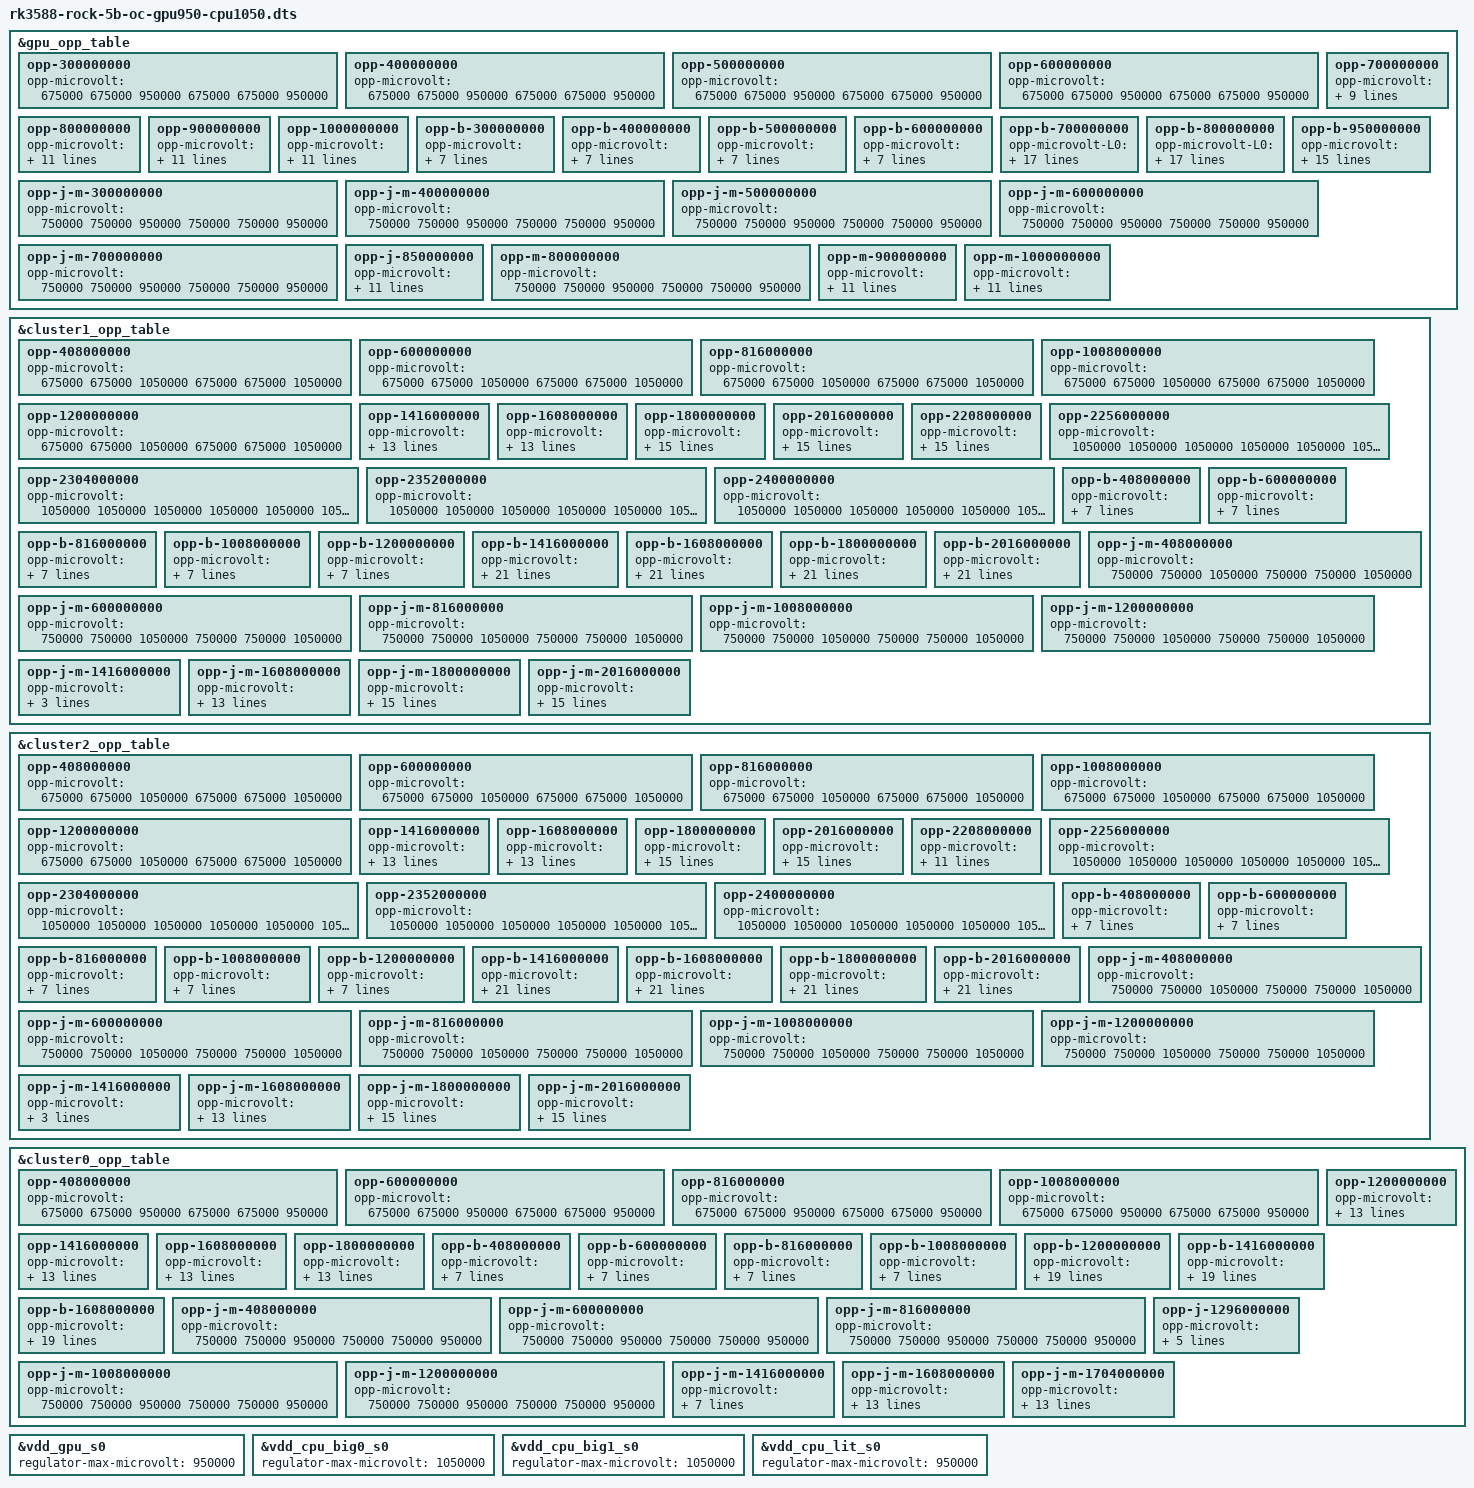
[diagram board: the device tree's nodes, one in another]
/dts-v1/;
/plugin/;

// RK3588 (ROCK 5B, vendor kernel) overclock: GPU 1 GHz OPP 950 mV, A76 top OPPs 1050 mV, A55 1.8 GHz OPP 925 mV.
// PVTPLL sets the real clocks from the voltage. Tested stable on one ROCK 5B (GPU PVTM level 5, A76 levels 6/7,
// A55 level 6) with glmark2 / all-core self-checking stress. Other chips (bins) may differ: if it does not boot,
// remove the FDTOVERLAYS line from extlinux/extlinux.conf on the boot partition from a PC.
// Generated by gen_oc.py from the kernel's rk3588-rock-5b.dtb; every OPP's max is raised so that the core and
// memory supplies (one regulator) can always step down.

&gpu_opp_table {
	opp-300000000 {
		opp-microvolt = <675000 675000 950000 675000 675000 950000>;
	};
	opp-400000000 {
		opp-microvolt = <675000 675000 950000 675000 675000 950000>;
	};
	opp-500000000 {
		opp-microvolt = <675000 675000 950000 675000 675000 950000>;
	};
	opp-600000000 {
		opp-microvolt = <675000 675000 950000 675000 675000 950000>;
	};
	opp-700000000 {
		opp-microvolt = <700000 700000 950000 700000 700000 950000>;
		opp-microvolt-L2 = <687500 687500 950000 687500 687500 950000>;
		opp-microvolt-L3 = <675000 675000 950000 675000 675000 950000>;
		opp-microvolt-L4 = <675000 675000 950000 675000 675000 950000>;
		opp-microvolt-L5 = <675000 675000 950000 675000 675000 950000>;
	};
	opp-800000000 {
		opp-microvolt = <750000 750000 950000 750000 750000 950000>;
		opp-microvolt-L1 = <737500 737500 950000 737500 737500 950000>;
		opp-microvolt-L2 = <725000 725000 950000 725000 725000 950000>;
		opp-microvolt-L3 = <712500 712500 950000 712500 712500 950000>;
		opp-microvolt-L4 = <700000 700000 950000 700000 700000 950000>;
		opp-microvolt-L5 = <700000 700000 950000 700000 700000 950000>;
	};
	opp-900000000 {
		opp-microvolt = <800000 800000 950000 800000 800000 950000>;
		opp-microvolt-L1 = <787500 787500 950000 787500 787500 950000>;
		opp-microvolt-L2 = <775000 775000 950000 775000 775000 950000>;
		opp-microvolt-L3 = <762500 762500 950000 762500 762500 950000>;
		opp-microvolt-L4 = <750000 750000 950000 750000 750000 950000>;
		opp-microvolt-L5 = <737500 737500 950000 737500 737500 950000>;
	};
	opp-1000000000 {
		opp-microvolt = <950000 950000 950000 950000 950000 950000>;
		opp-microvolt-L1 = <950000 950000 950000 950000 950000 950000>;
		opp-microvolt-L2 = <950000 950000 950000 950000 950000 950000>;
		opp-microvolt-L3 = <950000 950000 950000 950000 950000 950000>;
		opp-microvolt-L4 = <950000 950000 950000 950000 950000 950000>;
		opp-microvolt-L5 = <950000 950000 950000 950000 950000 950000>;
	};
	opp-b-300000000 {
		opp-microvolt = <675000 675000 950000 675000 675000 950000>;
		opp-microvolt-L0 = <712500 712500 950000 712500 712500 950000>;
		opp-microvolt-L1 = <700000 700000 950000 700000 700000 950000>;
		opp-microvolt-L2 = <687500 687500 950000 687500 687500 950000>;
	};
	opp-b-400000000 {
		opp-microvolt = <675000 675000 950000 675000 675000 950000>;
		opp-microvolt-L0 = <712500 712500 950000 712500 712500 950000>;
		opp-microvolt-L1 = <700000 700000 950000 700000 700000 950000>;
		opp-microvolt-L2 = <687500 687500 950000 687500 687500 950000>;
	};
	opp-b-500000000 {
		opp-microvolt = <675000 675000 950000 675000 675000 950000>;
		opp-microvolt-L0 = <712500 712500 950000 712500 712500 950000>;
		opp-microvolt-L1 = <700000 700000 950000 700000 700000 950000>;
		opp-microvolt-L2 = <687500 687500 950000 687500 687500 950000>;
	};
	opp-b-600000000 {
		opp-microvolt = <675000 675000 950000 675000 675000 950000>;
		opp-microvolt-L0 = <712500 712500 950000 712500 712500 950000>;
		opp-microvolt-L1 = <700000 700000 950000 700000 700000 950000>;
		opp-microvolt-L2 = <687500 687500 950000 687500 687500 950000>;
	};
	opp-b-700000000 {
		opp-microvolt-L0 = <737500 737500 950000 737500 737500 950000>;
		opp-microvolt-L1 = <725000 725000 950000 725000 725000 950000>;
		opp-microvolt-L2 = <712500 712500 950000 712500 712500 950000>;
		opp-microvolt-L3 = <700000 700000 950000 700000 700000 950000>;
		opp-microvolt-L4 = <700000 700000 950000 700000 700000 950000>;
		opp-microvolt-L5 = <687500 687500 950000 687500 687500 950000>;
		opp-microvolt-L6 = <675000 675000 950000 675000 675000 950000>;
		opp-microvolt-L7 = <675000 675000 950000 675000 675000 950000>;
		opp-microvolt-L8 = <675000 675000 950000 675000 675000 950000>;
	};
	opp-b-800000000 {
		opp-microvolt-L0 = <787500 787500 950000 787500 787500 950000>;
		opp-microvolt-L1 = <775000 775000 950000 775000 775000 950000>;
		opp-microvolt-L2 = <762500 762500 950000 762500 762500 950000>;
		opp-microvolt-L3 = <750000 750000 950000 750000 750000 950000>;
		opp-microvolt-L4 = <737500 737500 950000 737500 737500 950000>;
		opp-microvolt-L5 = <725000 725000 950000 725000 725000 950000>;
		opp-microvolt-L6 = <712500 712500 950000 712500 712500 950000>;
		opp-microvolt-L7 = <700000 700000 950000 700000 700000 950000>;
		opp-microvolt-L8 = <700000 700000 950000 700000 700000 950000>;
	};
	opp-b-950000000 {
		opp-microvolt = <850000 850000 950000 850000 850000 950000>;
		opp-microvolt-L2 = <837500 837500 950000 837500 837500 950000>;
		opp-microvolt-L3 = <825000 825000 950000 825000 825000 950000>;
		opp-microvolt-L4 = <812500 812500 950000 812500 812500 950000>;
		opp-microvolt-L5 = <800000 800000 950000 800000 800000 950000>;
		opp-microvolt-L6 = <787500 787500 950000 787500 787500 950000>;
		opp-microvolt-L7 = <775000 775000 950000 775000 775000 950000>;
		opp-microvolt-L8 = <762500 762500 950000 762500 762500 950000>;
	};
	opp-j-m-300000000 {
		opp-microvolt = <750000 750000 950000 750000 750000 950000>;
	};
	opp-j-m-400000000 {
		opp-microvolt = <750000 750000 950000 750000 750000 950000>;
	};
	opp-j-m-500000000 {
		opp-microvolt = <750000 750000 950000 750000 750000 950000>;
	};
	opp-j-m-600000000 {
		opp-microvolt = <750000 750000 950000 750000 750000 950000>;
	};
	opp-j-m-700000000 {
		opp-microvolt = <750000 750000 950000 750000 750000 950000>;
	};
	opp-j-850000000 {
		opp-microvolt = <787500 787500 950000 787500 787500 950000>;
		opp-microvolt-L1 = <775000 775000 950000 775000 775000 950000>;
		opp-microvolt-L2 = <762500 762500 950000 762500 762500 950000>;
		opp-microvolt-L3 = <750000 750000 950000 750000 750000 950000>;
		opp-microvolt-L4 = <750000 750000 950000 750000 750000 950000>;
		opp-microvolt-L5 = <750000 750000 950000 750000 750000 950000>;
	};
	opp-m-800000000 {
		opp-microvolt = <750000 750000 950000 750000 750000 950000>;
	};
	opp-m-900000000 {
		opp-microvolt = <800000 800000 950000 800000 800000 950000>;
		opp-microvolt-L1 = <787500 787500 950000 787500 787500 950000>;
		opp-microvolt-L2 = <775000 775000 950000 775000 775000 950000>;
		opp-microvolt-L3 = <762500 762500 950000 762500 762500 950000>;
		opp-microvolt-L4 = <750000 750000 950000 750000 750000 950000>;
		opp-microvolt-L5 = <750000 750000 950000 750000 750000 950000>;
	};
	opp-m-1000000000 {
		opp-microvolt = <850000 850000 950000 850000 850000 950000>;
		opp-microvolt-L1 = <837500 837500 950000 837500 837500 950000>;
		opp-microvolt-L2 = <825000 825000 950000 825000 825000 950000>;
		opp-microvolt-L3 = <812500 812500 950000 812500 812500 950000>;
		opp-microvolt-L4 = <800000 800000 950000 800000 800000 950000>;
		opp-microvolt-L5 = <787500 787500 950000 787500 787500 950000>;
	};
};
&cluster1_opp_table {
	opp-408000000 {
		opp-microvolt = <675000 675000 1050000 675000 675000 1050000>;
	};
	opp-600000000 {
		opp-microvolt = <675000 675000 1050000 675000 675000 1050000>;
	};
	opp-816000000 {
		opp-microvolt = <675000 675000 1050000 675000 675000 1050000>;
	};
	opp-1008000000 {
		opp-microvolt = <675000 675000 1050000 675000 675000 1050000>;
	};
	opp-1200000000 {
		opp-microvolt = <675000 675000 1050000 675000 675000 1050000>;
	};
	opp-1416000000 {
		opp-microvolt = <725000 725000 1050000 725000 725000 1050000>;
		opp-microvolt-L2 = <712500 712500 1050000 712500 712500 1050000>;
		opp-microvolt-L3 = <700000 700000 1050000 700000 700000 1050000>;
		opp-microvolt-L4 = <700000 700000 1050000 700000 700000 1050000>;
		opp-microvolt-L5 = <687500 687500 1050000 687500 687500 1050000>;
		opp-microvolt-L6 = <675000 675000 1050000 675000 675000 1050000>;
		opp-microvolt-L7 = <675000 675000 1050000 675000 675000 1050000>;
	};
	opp-1608000000 {
		opp-microvolt = <762500 762500 1050000 762500 762500 1050000>;
		opp-microvolt-L2 = <750000 750000 1050000 750000 750000 1050000>;
		opp-microvolt-L3 = <737500 737500 1050000 737500 737500 1050000>;
		opp-microvolt-L4 = <725000 725000 1050000 725000 725000 1050000>;
		opp-microvolt-L5 = <712500 712500 1050000 712500 712500 1050000>;
		opp-microvolt-L6 = <700000 700000 1050000 700000 700000 1050000>;
		opp-microvolt-L7 = <700000 700000 1050000 700000 700000 1050000>;
	};
	opp-1800000000 {
		opp-microvolt = <850000 850000 1050000 850000 850000 1050000>;
		opp-microvolt-L1 = <837500 837500 1050000 837500 837500 1050000>;
		opp-microvolt-L2 = <825000 825000 1050000 825000 825000 1050000>;
		opp-microvolt-L3 = <812500 812500 1050000 812500 812500 1050000>;
		opp-microvolt-L4 = <800000 800000 1050000 800000 800000 1050000>;
		opp-microvolt-L5 = <787500 787500 1050000 787500 787500 1050000>;
		opp-microvolt-L6 = <775000 775000 1050000 775000 775000 1050000>;
		opp-microvolt-L7 = <762500 762500 1050000 762500 762500 1050000>;
	};
	opp-2016000000 {
		opp-microvolt = <925000 925000 1050000 925000 925000 1050000>;
		opp-microvolt-L1 = <912500 912500 1050000 912500 912500 1050000>;
		opp-microvolt-L2 = <900000 900000 1050000 900000 900000 1050000>;
		opp-microvolt-L3 = <887500 887500 1050000 887500 887500 1050000>;
		opp-microvolt-L4 = <875000 875000 1050000 875000 875000 1050000>;
		opp-microvolt-L5 = <862500 862500 1050000 862500 862500 1050000>;
		opp-microvolt-L6 = <850000 850000 1050000 850000 850000 1050000>;
		opp-microvolt-L7 = <837500 837500 1050000 837500 837500 1050000>;
	};
	opp-2208000000 {
		opp-microvolt = <987500 987500 1050000 987500 987500 1050000>;
		opp-microvolt-L1 = <975000 975000 1050000 975000 975000 1050000>;
		opp-microvolt-L2 = <962500 962500 1050000 962500 962500 1050000>;
		opp-microvolt-L3 = <950000 950000 1050000 950000 950000 1050000>;
		opp-microvolt-L4 = <962500 962500 1050000 962500 962500 1050000>;
		opp-microvolt-L5 = <950000 950000 1050000 950000 950000 1050000>;
		opp-microvolt-L6 = <925000 925000 1050000 925000 925000 1050000>;
		opp-microvolt-L7 = <912500 912500 1050000 912500 912500 1050000>;
	};
	opp-2256000000 {
		opp-microvolt = <1050000 1050000 1050000 1050000 1050000 1050000>;
	};
	opp-2304000000 {
		opp-microvolt = <1050000 1050000 1050000 1050000 1050000 1050000>;
	};
	opp-2352000000 {
		opp-microvolt = <1050000 1050000 1050000 1050000 1050000 1050000>;
	};
	opp-2400000000 {
		opp-microvolt = <1050000 1050000 1050000 1050000 1050000 1050000>;
	};
	opp-b-408000000 {
		opp-microvolt = <675000 675000 1050000 675000 675000 1050000>;
		opp-microvolt-L0 = <712500 712500 1050000 712500 712500 1050000>;
		opp-microvolt-L1 = <700000 700000 1050000 700000 700000 1050000>;
		opp-microvolt-L2 = <687500 687500 1050000 687500 687500 1050000>;
	};
	opp-b-600000000 {
		opp-microvolt = <675000 675000 1050000 675000 675000 1050000>;
		opp-microvolt-L0 = <712500 712500 1050000 712500 712500 1050000>;
		opp-microvolt-L1 = <700000 700000 1050000 700000 700000 1050000>;
		opp-microvolt-L2 = <687500 687500 1050000 687500 687500 1050000>;
	};
	opp-b-816000000 {
		opp-microvolt = <675000 675000 1050000 675000 675000 1050000>;
		opp-microvolt-L0 = <712500 712500 1050000 712500 712500 1050000>;
		opp-microvolt-L1 = <700000 700000 1050000 700000 700000 1050000>;
		opp-microvolt-L2 = <687500 687500 1050000 687500 687500 1050000>;
	};
	opp-b-1008000000 {
		opp-microvolt = <675000 675000 1050000 675000 675000 1050000>;
		opp-microvolt-L0 = <712500 712500 1050000 712500 712500 1050000>;
		opp-microvolt-L1 = <700000 700000 1050000 700000 700000 1050000>;
		opp-microvolt-L2 = <687500 687500 1050000 687500 687500 1050000>;
	};
	opp-b-1200000000 {
		opp-microvolt = <675000 675000 1050000 675000 675000 1050000>;
		opp-microvolt-L0 = <712500 712500 1050000 712500 712500 1050000>;
		opp-microvolt-L1 = <700000 700000 1050000 700000 700000 1050000>;
		opp-microvolt-L2 = <687500 687500 1050000 687500 687500 1050000>;
	};
	opp-b-1416000000 {
		opp-microvolt = <750000 750000 1050000 750000 750000 1050000>;
		opp-microvolt-L1 = <737500 737500 1050000 737500 737500 1050000>;
		opp-microvolt-L2 = <737500 737500 1050000 737500 737500 1050000>;
		opp-microvolt-L3 = <725000 725000 1050000 725000 725000 1050000>;
		opp-microvolt-L4 = <725000 725000 1050000 725000 725000 1050000>;
		opp-microvolt-L5 = <712500 712500 1050000 712500 712500 1050000>;
		opp-microvolt-L6 = <700000 700000 1050000 700000 700000 1050000>;
		opp-microvolt-L7 = <700000 700000 1050000 700000 700000 1050000>;
		opp-microvolt-L8 = <687500 687500 1050000 687500 687500 1050000>;
		opp-microvolt-L9 = <675000 675000 1050000 675000 675000 1050000>;
		opp-microvolt-L10 = <675000 675000 1050000 675000 675000 1050000>;
	};
	opp-b-1608000000 {
		opp-microvolt = <800000 800000 1050000 800000 800000 1050000>;
		opp-microvolt-L1 = <787500 787500 1050000 787500 787500 1050000>;
		opp-microvolt-L2 = <775000 775000 1050000 775000 775000 1050000>;
		opp-microvolt-L3 = <762500 762500 1050000 762500 762500 1050000>;
		opp-microvolt-L4 = <762500 762500 1050000 762500 762500 1050000>;
		opp-microvolt-L5 = <750000 750000 1050000 750000 750000 1050000>;
		opp-microvolt-L6 = <737500 737500 1050000 737500 737500 1050000>;
		opp-microvolt-L7 = <725000 725000 1050000 725000 725000 1050000>;
		opp-microvolt-L8 = <712500 712500 1050000 712500 712500 1050000>;
		opp-microvolt-L9 = <700000 700000 1050000 700000 700000 1050000>;
		opp-microvolt-L10 = <700000 700000 1050000 700000 700000 1050000>;
	};
	opp-b-1800000000 {
		opp-microvolt = <875000 875000 1050000 875000 875000 1050000>;
		opp-microvolt-L1 = <875000 875000 1050000 875000 875000 1050000>;
		opp-microvolt-L2 = <862500 862500 1050000 862500 862500 1050000>;
		opp-microvolt-L3 = <850000 850000 1050000 850000 850000 1050000>;
		opp-microvolt-L4 = <837500 837500 1050000 837500 837500 1050000>;
		opp-microvolt-L5 = <825000 825000 1050000 825000 825000 1050000>;
		opp-microvolt-L6 = <812500 812500 1050000 812500 812500 1050000>;
		opp-microvolt-L7 = <800000 800000 1050000 800000 800000 1050000>;
		opp-microvolt-L8 = <787500 787500 1050000 787500 787500 1050000>;
		opp-microvolt-L9 = <775000 775000 1050000 775000 775000 1050000>;
		opp-microvolt-L10 = <762500 762500 1050000 762500 762500 1050000>;
	};
	opp-b-2016000000 {
		opp-microvolt = <962500 962500 1050000 962500 962500 1050000>;
		opp-microvolt-L1 = <950000 950000 1050000 950000 950000 1050000>;
		opp-microvolt-L2 = <937500 937500 1050000 937500 937500 1050000>;
		opp-microvolt-L3 = <925000 925000 1050000 925000 925000 1050000>;
		opp-microvolt-L4 = <912500 912500 1050000 912500 912500 1050000>;
		opp-microvolt-L5 = <900000 900000 1050000 900000 900000 1050000>;
		opp-microvolt-L6 = <887500 887500 1050000 887500 887500 1050000>;
		opp-microvolt-L7 = <875000 875000 1050000 875000 875000 1050000>;
		opp-microvolt-L8 = <862500 862500 1050000 862500 862500 1050000>;
		opp-microvolt-L9 = <850000 850000 1050000 850000 850000 1050000>;
		opp-microvolt-L10 = <837500 837500 1050000 837500 837500 1050000>;
	};
	opp-j-m-408000000 {
		opp-microvolt = <750000 750000 1050000 750000 750000 1050000>;
	};
	opp-j-m-600000000 {
		opp-microvolt = <750000 750000 1050000 750000 750000 1050000>;
	};
	opp-j-m-816000000 {
		opp-microvolt = <750000 750000 1050000 750000 750000 1050000>;
	};
	opp-j-m-1008000000 {
		opp-microvolt = <750000 750000 1050000 750000 750000 1050000>;
	};
	opp-j-m-1200000000 {
		opp-microvolt = <750000 750000 1050000 750000 750000 1050000>;
	};
	opp-j-m-1416000000 {
		opp-microvolt = <750000 750000 1050000 750000 750000 1050000>;
		opp-microvolt-L0 = <762500 762500 1050000 762500 762500 1050000>;
	};
	opp-j-m-1608000000 {
		opp-microvolt = <787500 787500 1050000 787500 787500 1050000>;
		opp-microvolt-L2 = <775000 775000 1050000 775000 775000 1050000>;
		opp-microvolt-L3 = <762500 762500 1050000 762500 762500 1050000>;
		opp-microvolt-L4 = <750000 750000 1050000 750000 750000 1050000>;
		opp-microvolt-L5 = <750000 750000 1050000 750000 750000 1050000>;
		opp-microvolt-L6 = <750000 750000 1050000 750000 750000 1050000>;
		opp-microvolt-L7 = <750000 750000 1050000 750000 750000 1050000>;
	};
	opp-j-m-1800000000 {
		opp-microvolt = <875000 875000 1050000 875000 875000 1050000>;
		opp-microvolt-L1 = <862500 862500 1050000 862500 862500 1050000>;
		opp-microvolt-L2 = <850000 850000 1050000 850000 850000 1050000>;
		opp-microvolt-L3 = <837500 837500 1050000 837500 837500 1050000>;
		opp-microvolt-L4 = <825000 825000 1050000 825000 825000 1050000>;
		opp-microvolt-L5 = <812500 812500 1050000 812500 812500 1050000>;
		opp-microvolt-L6 = <800000 800000 1050000 800000 800000 1050000>;
		opp-microvolt-L7 = <787500 787500 1050000 787500 787500 1050000>;
	};
	opp-j-m-2016000000 {
		opp-microvolt = <950000 950000 1050000 950000 950000 1050000>;
		opp-microvolt-L1 = <950000 950000 1050000 950000 950000 1050000>;
		opp-microvolt-L2 = <937500 937500 1050000 937500 937500 1050000>;
		opp-microvolt-L3 = <925000 925000 1050000 925000 925000 1050000>;
		opp-microvolt-L4 = <912500 912500 1050000 912500 912500 1050000>;
		opp-microvolt-L5 = <900000 900000 1050000 900000 900000 1050000>;
		opp-microvolt-L6 = <887500 887500 1050000 887500 887500 1050000>;
		opp-microvolt-L7 = <875000 875000 1050000 875000 875000 1050000>;
	};
};
&cluster2_opp_table {
	opp-408000000 {
		opp-microvolt = <675000 675000 1050000 675000 675000 1050000>;
	};
	opp-600000000 {
		opp-microvolt = <675000 675000 1050000 675000 675000 1050000>;
	};
	opp-816000000 {
		opp-microvolt = <675000 675000 1050000 675000 675000 1050000>;
	};
	opp-1008000000 {
		opp-microvolt = <675000 675000 1050000 675000 675000 1050000>;
	};
	opp-1200000000 {
		opp-microvolt = <675000 675000 1050000 675000 675000 1050000>;
	};
	opp-1416000000 {
		opp-microvolt = <725000 725000 1050000 725000 725000 1050000>;
		opp-microvolt-L2 = <712500 712500 1050000 712500 712500 1050000>;
		opp-microvolt-L3 = <700000 700000 1050000 700000 700000 1050000>;
		opp-microvolt-L4 = <700000 700000 1050000 700000 700000 1050000>;
		opp-microvolt-L5 = <687500 687500 1050000 687500 687500 1050000>;
		opp-microvolt-L6 = <675000 675000 1050000 675000 675000 1050000>;
		opp-microvolt-L7 = <675000 675000 1050000 675000 675000 1050000>;
	};
	opp-1608000000 {
		opp-microvolt = <762500 762500 1050000 762500 762500 1050000>;
		opp-microvolt-L2 = <750000 750000 1050000 750000 750000 1050000>;
		opp-microvolt-L3 = <737500 737500 1050000 737500 737500 1050000>;
		opp-microvolt-L4 = <725000 725000 1050000 725000 725000 1050000>;
		opp-microvolt-L5 = <712500 712500 1050000 712500 712500 1050000>;
		opp-microvolt-L6 = <700000 700000 1050000 700000 700000 1050000>;
		opp-microvolt-L7 = <700000 700000 1050000 700000 700000 1050000>;
	};
	opp-1800000000 {
		opp-microvolt = <850000 850000 1050000 850000 850000 1050000>;
		opp-microvolt-L1 = <837500 837500 1050000 837500 837500 1050000>;
		opp-microvolt-L2 = <825000 825000 1050000 825000 825000 1050000>;
		opp-microvolt-L3 = <812500 812500 1050000 812500 812500 1050000>;
		opp-microvolt-L4 = <800000 800000 1050000 800000 800000 1050000>;
		opp-microvolt-L5 = <787500 787500 1050000 787500 787500 1050000>;
		opp-microvolt-L6 = <775000 775000 1050000 775000 775000 1050000>;
		opp-microvolt-L7 = <762500 762500 1050000 762500 762500 1050000>;
	};
	opp-2016000000 {
		opp-microvolt = <925000 925000 1050000 925000 925000 1050000>;
		opp-microvolt-L1 = <912500 912500 1050000 912500 912500 1050000>;
		opp-microvolt-L2 = <900000 900000 1050000 900000 900000 1050000>;
		opp-microvolt-L3 = <887500 887500 1050000 887500 887500 1050000>;
		opp-microvolt-L4 = <875000 875000 1050000 875000 875000 1050000>;
		opp-microvolt-L5 = <862500 862500 1050000 862500 862500 1050000>;
		opp-microvolt-L6 = <850000 850000 1050000 850000 850000 1050000>;
		opp-microvolt-L7 = <837500 837500 1050000 837500 837500 1050000>;
	};
	opp-2208000000 {
		opp-microvolt = <987500 987500 1050000 987500 987500 1050000>;
		opp-microvolt-L3 = <975000 975000 1050000 975000 975000 1050000>;
		opp-microvolt-L4 = <962500 962500 1050000 962500 962500 1050000>;
		opp-microvolt-L5 = <950000 950000 1050000 950000 950000 1050000>;
		opp-microvolt-L6 = <925000 925000 1050000 925000 925000 1050000>;
		opp-microvolt-L7 = <912500 912500 1050000 912500 912500 1050000>;
	};
	opp-2256000000 {
		opp-microvolt = <1050000 1050000 1050000 1050000 1050000 1050000>;
	};
	opp-2304000000 {
		opp-microvolt = <1050000 1050000 1050000 1050000 1050000 1050000>;
	};
	opp-2352000000 {
		opp-microvolt = <1050000 1050000 1050000 1050000 1050000 1050000>;
	};
	opp-2400000000 {
		opp-microvolt = <1050000 1050000 1050000 1050000 1050000 1050000>;
	};
	opp-b-408000000 {
		opp-microvolt = <675000 675000 1050000 675000 675000 1050000>;
		opp-microvolt-L0 = <712500 712500 1050000 712500 712500 1050000>;
		opp-microvolt-L1 = <700000 700000 1050000 700000 700000 1050000>;
		opp-microvolt-L2 = <687500 687500 1050000 687500 687500 1050000>;
	};
	opp-b-600000000 {
		opp-microvolt = <675000 675000 1050000 675000 675000 1050000>;
		opp-microvolt-L0 = <712500 712500 1050000 712500 712500 1050000>;
		opp-microvolt-L1 = <700000 700000 1050000 700000 700000 1050000>;
		opp-microvolt-L2 = <687500 687500 1050000 687500 687500 1050000>;
	};
	opp-b-816000000 {
		opp-microvolt = <675000 675000 1050000 675000 675000 1050000>;
		opp-microvolt-L0 = <712500 712500 1050000 712500 712500 1050000>;
		opp-microvolt-L1 = <700000 700000 1050000 700000 700000 1050000>;
		opp-microvolt-L2 = <687500 687500 1050000 687500 687500 1050000>;
	};
	opp-b-1008000000 {
		opp-microvolt = <675000 675000 1050000 675000 675000 1050000>;
		opp-microvolt-L0 = <712500 712500 1050000 712500 712500 1050000>;
		opp-microvolt-L1 = <700000 700000 1050000 700000 700000 1050000>;
		opp-microvolt-L2 = <687500 687500 1050000 687500 687500 1050000>;
	};
	opp-b-1200000000 {
		opp-microvolt = <675000 675000 1050000 675000 675000 1050000>;
		opp-microvolt-L0 = <712500 712500 1050000 712500 712500 1050000>;
		opp-microvolt-L1 = <700000 700000 1050000 700000 700000 1050000>;
		opp-microvolt-L2 = <687500 687500 1050000 687500 687500 1050000>;
	};
	opp-b-1416000000 {
		opp-microvolt = <750000 750000 1050000 750000 750000 1050000>;
		opp-microvolt-L1 = <737500 737500 1050000 737500 737500 1050000>;
		opp-microvolt-L2 = <737500 737500 1050000 737500 737500 1050000>;
		opp-microvolt-L3 = <725000 725000 1050000 725000 725000 1050000>;
		opp-microvolt-L4 = <725000 725000 1050000 725000 725000 1050000>;
		opp-microvolt-L5 = <712500 712500 1050000 712500 712500 1050000>;
		opp-microvolt-L6 = <700000 700000 1050000 700000 700000 1050000>;
		opp-microvolt-L7 = <700000 700000 1050000 700000 700000 1050000>;
		opp-microvolt-L8 = <687500 687500 1050000 687500 687500 1050000>;
		opp-microvolt-L9 = <675000 675000 1050000 675000 675000 1050000>;
		opp-microvolt-L10 = <675000 675000 1050000 675000 675000 1050000>;
	};
	opp-b-1608000000 {
		opp-microvolt = <800000 800000 1050000 800000 800000 1050000>;
		opp-microvolt-L1 = <787500 787500 1050000 787500 787500 1050000>;
		opp-microvolt-L2 = <775000 775000 1050000 775000 775000 1050000>;
		opp-microvolt-L3 = <762500 762500 1050000 762500 762500 1050000>;
		opp-microvolt-L4 = <762500 762500 1050000 762500 762500 1050000>;
		opp-microvolt-L5 = <750000 750000 1050000 750000 750000 1050000>;
		opp-microvolt-L6 = <737500 737500 1050000 737500 737500 1050000>;
		opp-microvolt-L7 = <725000 725000 1050000 725000 725000 1050000>;
		opp-microvolt-L8 = <712500 712500 1050000 712500 712500 1050000>;
		opp-microvolt-L9 = <700000 700000 1050000 700000 700000 1050000>;
		opp-microvolt-L10 = <700000 700000 1050000 700000 700000 1050000>;
	};
	opp-b-1800000000 {
		opp-microvolt = <875000 875000 1050000 875000 875000 1050000>;
		opp-microvolt-L1 = <875000 875000 1050000 875000 875000 1050000>;
		opp-microvolt-L2 = <862500 862500 1050000 862500 862500 1050000>;
		opp-microvolt-L3 = <850000 850000 1050000 850000 850000 1050000>;
		opp-microvolt-L4 = <837500 837500 1050000 837500 837500 1050000>;
		opp-microvolt-L5 = <825000 825000 1050000 825000 825000 1050000>;
		opp-microvolt-L6 = <812500 812500 1050000 812500 812500 1050000>;
		opp-microvolt-L7 = <800000 800000 1050000 800000 800000 1050000>;
		opp-microvolt-L8 = <787500 787500 1050000 787500 787500 1050000>;
		opp-microvolt-L9 = <775000 775000 1050000 775000 775000 1050000>;
		opp-microvolt-L10 = <762500 762500 1050000 762500 762500 1050000>;
	};
	opp-b-2016000000 {
		opp-microvolt = <962500 962500 1050000 962500 962500 1050000>;
		opp-microvolt-L1 = <950000 950000 1050000 950000 950000 1050000>;
		opp-microvolt-L2 = <937500 937500 1050000 937500 937500 1050000>;
		opp-microvolt-L3 = <925000 925000 1050000 925000 925000 1050000>;
		opp-microvolt-L4 = <912500 912500 1050000 912500 912500 1050000>;
		opp-microvolt-L5 = <900000 900000 1050000 900000 900000 1050000>;
		opp-microvolt-L6 = <887500 887500 1050000 887500 887500 1050000>;
		opp-microvolt-L7 = <875000 875000 1050000 875000 875000 1050000>;
		opp-microvolt-L8 = <862500 862500 1050000 862500 862500 1050000>;
		opp-microvolt-L9 = <850000 850000 1050000 850000 850000 1050000>;
		opp-microvolt-L10 = <837500 837500 1050000 837500 837500 1050000>;
	};
	opp-j-m-408000000 {
		opp-microvolt = <750000 750000 1050000 750000 750000 1050000>;
	};
	opp-j-m-600000000 {
		opp-microvolt = <750000 750000 1050000 750000 750000 1050000>;
	};
	opp-j-m-816000000 {
		opp-microvolt = <750000 750000 1050000 750000 750000 1050000>;
	};
	opp-j-m-1008000000 {
		opp-microvolt = <750000 750000 1050000 750000 750000 1050000>;
	};
	opp-j-m-1200000000 {
		opp-microvolt = <750000 750000 1050000 750000 750000 1050000>;
	};
	opp-j-m-1416000000 {
		opp-microvolt = <750000 750000 1050000 750000 750000 1050000>;
		opp-microvolt-L0 = <762500 762500 1050000 762500 762500 1050000>;
	};
	opp-j-m-1608000000 {
		opp-microvolt = <787500 787500 1050000 787500 787500 1050000>;
		opp-microvolt-L2 = <775000 775000 1050000 775000 775000 1050000>;
		opp-microvolt-L3 = <762500 762500 1050000 762500 762500 1050000>;
		opp-microvolt-L4 = <750000 750000 1050000 750000 750000 1050000>;
		opp-microvolt-L5 = <750000 750000 1050000 750000 750000 1050000>;
		opp-microvolt-L6 = <750000 750000 1050000 750000 750000 1050000>;
		opp-microvolt-L7 = <750000 750000 1050000 750000 750000 1050000>;
	};
	opp-j-m-1800000000 {
		opp-microvolt = <875000 875000 1050000 875000 875000 1050000>;
		opp-microvolt-L1 = <862500 862500 1050000 862500 862500 1050000>;
		opp-microvolt-L2 = <850000 850000 1050000 850000 850000 1050000>;
		opp-microvolt-L3 = <837500 837500 1050000 837500 837500 1050000>;
		opp-microvolt-L4 = <825000 825000 1050000 825000 825000 1050000>;
		opp-microvolt-L5 = <812500 812500 1050000 812500 812500 1050000>;
		opp-microvolt-L6 = <800000 800000 1050000 800000 800000 1050000>;
		opp-microvolt-L7 = <787500 787500 1050000 787500 787500 1050000>;
	};
	opp-j-m-2016000000 {
		opp-microvolt = <950000 950000 1050000 950000 950000 1050000>;
		opp-microvolt-L1 = <950000 950000 1050000 950000 950000 1050000>;
		opp-microvolt-L2 = <937500 937500 1050000 937500 937500 1050000>;
		opp-microvolt-L3 = <925000 925000 1050000 925000 925000 1050000>;
		opp-microvolt-L4 = <912500 912500 1050000 912500 912500 1050000>;
		opp-microvolt-L5 = <900000 900000 1050000 900000 900000 1050000>;
		opp-microvolt-L6 = <887500 887500 1050000 887500 887500 1050000>;
		opp-microvolt-L7 = <875000 875000 1050000 875000 875000 1050000>;
	};
};
&cluster0_opp_table {
	opp-408000000 {
		opp-microvolt = <675000 675000 950000 675000 675000 950000>;
	};
	opp-600000000 {
		opp-microvolt = <675000 675000 950000 675000 675000 950000>;
	};
	opp-816000000 {
		opp-microvolt = <675000 675000 950000 675000 675000 950000>;
	};
	opp-1008000000 {
		opp-microvolt = <675000 675000 950000 675000 675000 950000>;
	};
	opp-1200000000 {
		opp-microvolt = <712500 712500 950000 712500 712500 950000>;
		opp-microvolt-L1 = <700000 700000 950000 700000 700000 950000>;
		opp-microvolt-L2 = <700000 700000 950000 700000 700000 950000>;
		opp-microvolt-L3 = <687500 687500 950000 687500 687500 950000>;
		opp-microvolt-L4 = <675000 675000 950000 675000 675000 950000>;
		opp-microvolt-L5 = <675000 675000 950000 675000 675000 950000>;
		opp-microvolt-L6 = <675000 675000 950000 675000 675000 950000>;
	};
	opp-1416000000 {
		opp-microvolt = <762500 762500 950000 762500 762500 950000>;
		opp-microvolt-L1 = <750000 750000 950000 750000 750000 950000>;
		opp-microvolt-L2 = <737500 737500 950000 737500 737500 950000>;
		opp-microvolt-L3 = <725000 725000 950000 725000 725000 950000>;
		opp-microvolt-L4 = <725000 725000 950000 725000 725000 950000>;
		opp-microvolt-L5 = <712500 712500 950000 712500 712500 950000>;
		opp-microvolt-L6 = <712500 712500 950000 712500 712500 950000>;
	};
	opp-1608000000 {
		opp-microvolt = <850000 850000 950000 850000 850000 950000>;
		opp-microvolt-L1 = <837500 837500 950000 837500 837500 950000>;
		opp-microvolt-L2 = <825000 825000 950000 825000 825000 950000>;
		opp-microvolt-L3 = <812500 812500 950000 812500 812500 950000>;
		opp-microvolt-L4 = <800000 800000 950000 800000 800000 950000>;
		opp-microvolt-L5 = <800000 800000 950000 800000 800000 950000>;
		opp-microvolt-L6 = <787500 787500 950000 787500 787500 950000>;
	};
	opp-1800000000 {
		opp-microvolt = <925000 925000 925000 925000 925000 925000>;
		opp-microvolt-L1 = <925000 925000 925000 925000 925000 925000>;
		opp-microvolt-L2 = <925000 925000 925000 925000 925000 925000>;
		opp-microvolt-L3 = <925000 925000 925000 925000 925000 925000>;
		opp-microvolt-L4 = <925000 925000 925000 925000 925000 925000>;
		opp-microvolt-L5 = <925000 925000 925000 925000 925000 925000>;
		opp-microvolt-L6 = <925000 925000 925000 925000 925000 925000>;
	};
	opp-b-408000000 {
		opp-microvolt = <675000 675000 950000 675000 675000 950000>;
		opp-microvolt-L0 = <712500 712500 950000 712500 712500 950000>;
		opp-microvolt-L1 = <700000 700000 950000 700000 700000 950000>;
		opp-microvolt-L2 = <687500 687500 950000 687500 687500 950000>;
	};
	opp-b-600000000 {
		opp-microvolt = <675000 675000 950000 675000 675000 950000>;
		opp-microvolt-L0 = <712500 712500 950000 712500 712500 950000>;
		opp-microvolt-L1 = <700000 700000 950000 700000 700000 950000>;
		opp-microvolt-L2 = <687500 687500 950000 687500 687500 950000>;
	};
	opp-b-816000000 {
		opp-microvolt = <675000 675000 950000 675000 675000 950000>;
		opp-microvolt-L0 = <712500 712500 950000 712500 712500 950000>;
		opp-microvolt-L1 = <700000 700000 950000 700000 700000 950000>;
		opp-microvolt-L2 = <687500 687500 950000 687500 687500 950000>;
	};
	opp-b-1008000000 {
		opp-microvolt = <675000 675000 950000 675000 675000 950000>;
		opp-microvolt-L0 = <712500 712500 950000 712500 712500 950000>;
		opp-microvolt-L1 = <700000 700000 950000 700000 700000 950000>;
		opp-microvolt-L2 = <687500 687500 950000 687500 687500 950000>;
	};
	opp-b-1200000000 {
		opp-microvolt = <750000 750000 950000 750000 750000 950000>;
		opp-microvolt-L1 = <737500 737500 950000 737500 737500 950000>;
		opp-microvolt-L2 = <725000 725000 950000 725000 725000 950000>;
		opp-microvolt-L3 = <712500 712500 950000 712500 712500 950000>;
		opp-microvolt-L4 = <700000 700000 950000 700000 700000 950000>;
		opp-microvolt-L5 = <700000 700000 950000 700000 700000 950000>;
		opp-microvolt-L6 = <687500 687500 950000 687500 687500 950000>;
		opp-microvolt-L7 = <675000 675000 950000 675000 675000 950000>;
		opp-microvolt-L8 = <675000 675000 950000 675000 675000 950000>;
		opp-microvolt-L9 = <675000 675000 950000 675000 675000 950000>;
	};
	opp-b-1416000000 {
		opp-microvolt = <800000 800000 950000 800000 800000 950000>;
		opp-microvolt-L1 = <787500 787500 950000 787500 787500 950000>;
		opp-microvolt-L2 = <775000 775000 950000 775000 775000 950000>;
		opp-microvolt-L3 = <762500 762500 950000 762500 762500 950000>;
		opp-microvolt-L4 = <750000 750000 950000 750000 750000 950000>;
		opp-microvolt-L5 = <737500 737500 950000 737500 737500 950000>;
		opp-microvolt-L6 = <725000 725000 950000 725000 725000 950000>;
		opp-microvolt-L7 = <725000 725000 950000 725000 725000 950000>;
		opp-microvolt-L8 = <712500 712500 950000 712500 712500 950000>;
		opp-microvolt-L9 = <712500 712500 950000 712500 712500 950000>;
	};
	opp-b-1608000000 {
		opp-microvolt = <887500 887500 950000 887500 887500 950000>;
		opp-microvolt-L1 = <875000 875000 950000 875000 875000 950000>;
		opp-microvolt-L2 = <862500 862500 950000 862500 862500 950000>;
		opp-microvolt-L3 = <850000 850000 950000 850000 850000 950000>;
		opp-microvolt-L4 = <837500 837500 950000 837500 837500 950000>;
		opp-microvolt-L5 = <825000 825000 950000 825000 825000 950000>;
		opp-microvolt-L6 = <812500 812500 950000 812500 812500 950000>;
		opp-microvolt-L7 = <800000 800000 950000 800000 800000 950000>;
		opp-microvolt-L8 = <800000 800000 950000 800000 800000 950000>;
		opp-microvolt-L9 = <787500 787500 950000 787500 787500 950000>;
	};
	opp-j-m-408000000 {
		opp-microvolt = <750000 750000 950000 750000 750000 950000>;
	};
	opp-j-m-600000000 {
		opp-microvolt = <750000 750000 950000 750000 750000 950000>;
	};
	opp-j-m-816000000 {
		opp-microvolt = <750000 750000 950000 750000 750000 950000>;
	};
	opp-j-m-1008000000 {
		opp-microvolt = <750000 750000 950000 750000 750000 950000>;
	};
	opp-j-m-1200000000 {
		opp-microvolt = <750000 750000 950000 750000 750000 950000>;
	};
	opp-j-1296000000 {
		opp-microvolt = <750000 750000 950000 750000 750000 950000>;
		opp-microvolt-L0 = <775000 775000 950000 775000 775000 950000>;
		opp-microvolt-L1 = <762500 762500 950000 762500 762500 950000>;
	};
	opp-j-m-1416000000 {
		opp-microvolt = <750000 750000 950000 750000 750000 950000>;
		opp-microvolt-L0 = <787500 787500 950000 787500 787500 950000>;
		opp-microvolt-L1 = <775000 775000 950000 775000 775000 950000>;
		opp-microvolt-L2 = <762500 762500 950000 762500 762500 950000>;
	};
	opp-j-m-1608000000 {
		opp-microvolt = <887500 887500 950000 887500 887500 950000>;
		opp-microvolt-L1 = <875000 875000 950000 875000 875000 950000>;
		opp-microvolt-L2 = <862500 862500 950000 862500 862500 950000>;
		opp-microvolt-L3 = <850000 850000 950000 850000 850000 950000>;
		opp-microvolt-L4 = <837500 837500 950000 837500 837500 950000>;
		opp-microvolt-L5 = <825000 825000 950000 825000 825000 950000>;
		opp-microvolt-L6 = <812500 812500 950000 812500 812500 950000>;
	};
	opp-j-m-1704000000 {
		opp-microvolt = <937500 937500 950000 937500 937500 950000>;
		opp-microvolt-L1 = <925000 925000 950000 925000 925000 950000>;
		opp-microvolt-L2 = <912500 912500 950000 912500 912500 950000>;
		opp-microvolt-L3 = <900000 900000 950000 900000 900000 950000>;
		opp-microvolt-L4 = <887500 887500 950000 887500 887500 950000>;
		opp-microvolt-L5 = <875000 875000 950000 875000 875000 950000>;
		opp-microvolt-L6 = <862500 862500 950000 862500 862500 950000>;
	};
};
&vdd_gpu_s0 { regulator-max-microvolt = <950000>; };
&vdd_cpu_big0_s0 { regulator-max-microvolt = <1050000>; };
&vdd_cpu_big1_s0 { regulator-max-microvolt = <1050000>; };
&vdd_cpu_lit_s0 { regulator-max-microvolt = <950000>; };
